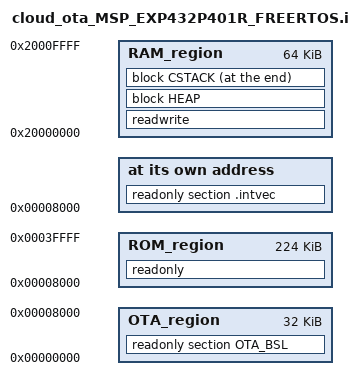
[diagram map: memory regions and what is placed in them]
define symbol __ICFEDIT_intvec_start__ = 0x00008000;

define symbol __ICFEDIT_region_ROM_start__   = 0x00008000;
define symbol __ICFEDIT_region_ROM_end__     = 0x0003FFFF;
define symbol __ICFEDIT_region_RAM_start__   = 0x20000000;
define symbol __ICFEDIT_region_RAM_end__     = 0x2000FFFF;

define symbol __ICFEDIT_size_cstack__   = 0x1000;
define symbol __ICFEDIT_size_heap__     = 0x2000;

define memory mem with size = 4G;
define region ROM_region   = mem:[from __ICFEDIT_region_ROM_start__   to __ICFEDIT_region_ROM_end__];
define region RAM_region   = mem:[from __ICFEDIT_region_RAM_start__   to __ICFEDIT_region_RAM_end__];

define block HEAP      with alignment = 8, size = __ICFEDIT_size_heap__     { };
define block CSTACK    with alignment = 8, size = __ICFEDIT_size_cstack__   { section .stack };
do not initialize { section .stack};

/* Export stack top symbol. Used by startup file */
define exported symbol STACK_TOP = __ICFEDIT_region_RAM_end__ + 1;

initialize by copy { readwrite };
do not initialize  { section .noinit };

place at address mem:__ICFEDIT_intvec_start__ { readonly section .intvec };
place in ROM_region   { readonly };
place in RAM_region   { readwrite,
                        block HEAP };
place at end of RAM_region { block CSTACK };

/* Section for OTA bootloader */
define region OTA_region = mem:[ from 0x0000 to 0x8000 ];
place in OTA_region { readonly section OTA_BSL };
